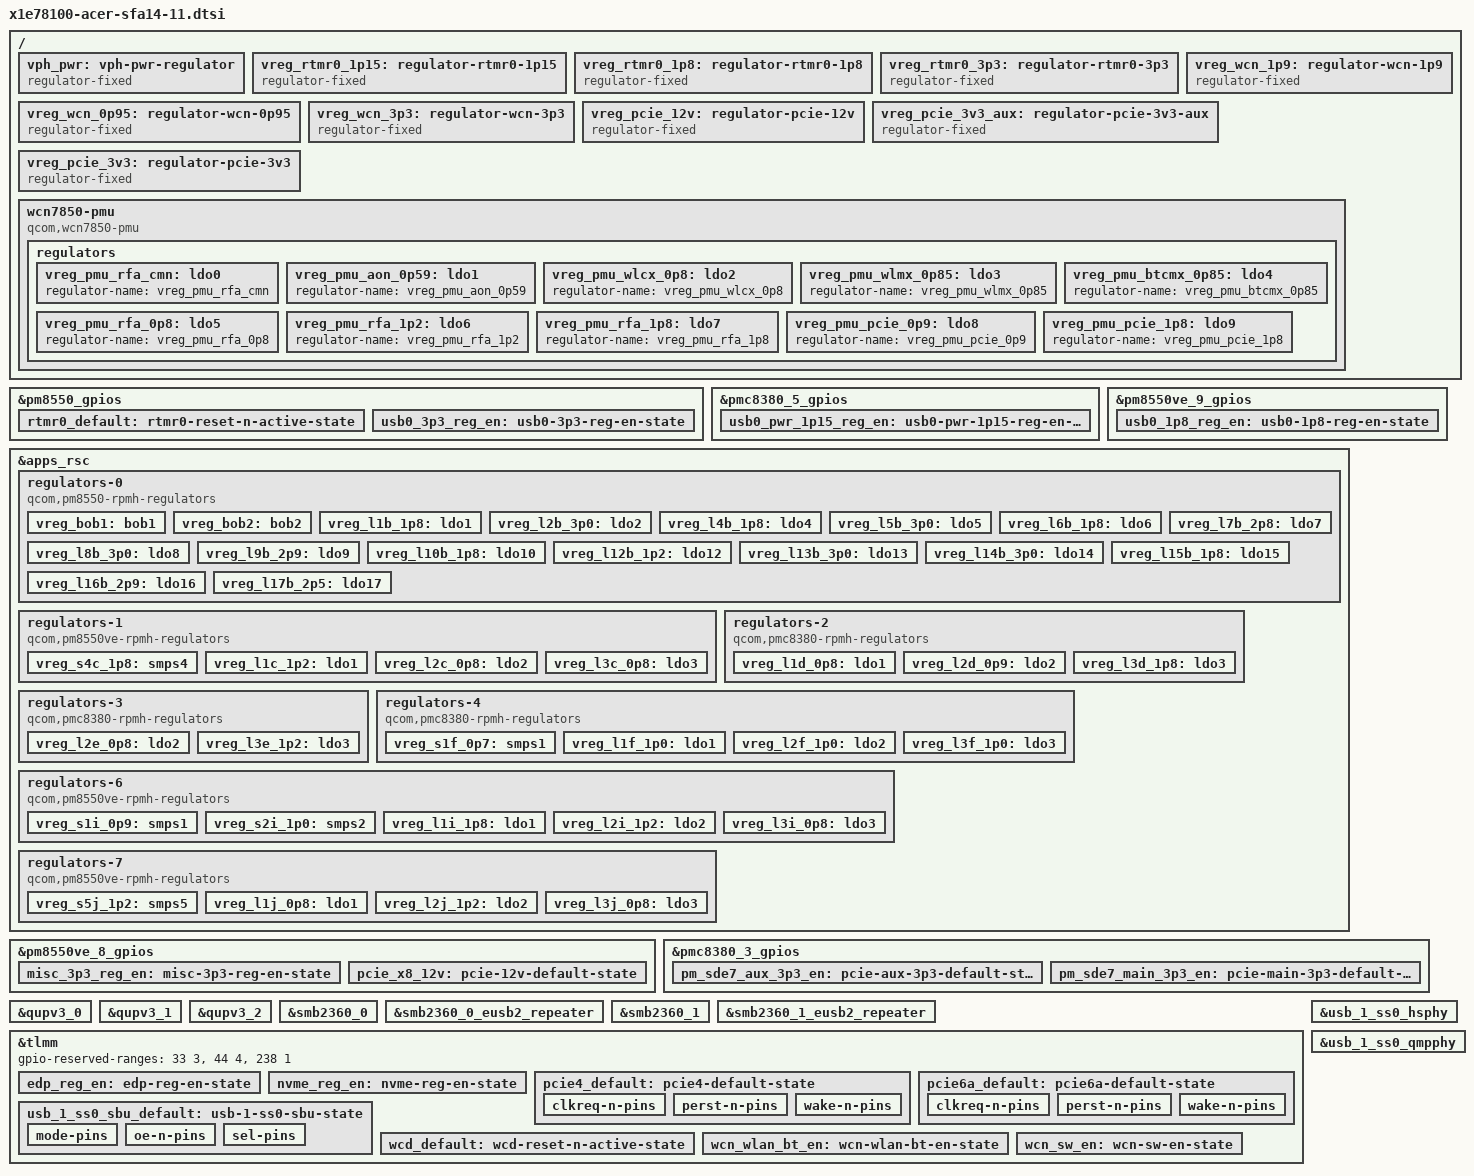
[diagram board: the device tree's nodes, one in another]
// SPDX-License-Identifier: BSD-3-Clause
/*
 * Copyright (c) 2023, Qualcomm Innovation Center, Inc. All rights reserved.
 * Copyright (c) 2025, Linaro Limited
 * Copyright (c) 2025, Zimo Zhang
 */

/dts-v1/;

#include <dt-bindings/gpio/gpio.h>
#include <dt-bindings/pinctrl/qcom,pmic-gpio.h>
#include <dt-bindings/regulator/qcom,rpmh-regulator.h>

#include "hamoa.dtsi"
#include "hamoa-pmics.dtsi"

/ {
	vph_pwr: vph-pwr-regulator {
		compatible = "regulator-fixed";

		regulator-name = "vph_pwr";
		regulator-min-microvolt = <3700000>;
		regulator-max-microvolt = <3700000>;

		regulator-always-on;
		regulator-boot-on;
	};

	vreg_rtmr0_1p15: regulator-rtmr0-1p15 {
		compatible = "regulator-fixed";

		regulator-name = "VREG_RTMR0_1P15";
		regulator-min-microvolt = <1150000>;
		regulator-max-microvolt = <1150000>;

		gpio = <&pmc8380_5_gpios 8 GPIO_ACTIVE_HIGH>;
		enable-active-high;

		pinctrl-0 = <&usb0_pwr_1p15_reg_en>;
		pinctrl-names = "default";

		regulator-boot-on;
	};

	vreg_rtmr0_1p8: regulator-rtmr0-1p8 {
		compatible = "regulator-fixed";

		regulator-name = "VREG_RTMR0_1P8";
		regulator-min-microvolt = <1800000>;
		regulator-max-microvolt = <1800000>;

		gpio = <&pm8550ve_9_gpios 8 GPIO_ACTIVE_HIGH>;
		enable-active-high;

		pinctrl-0 = <&usb0_1p8_reg_en>;
		pinctrl-names = "default";

		regulator-boot-on;
	};

	vreg_rtmr0_3p3: regulator-rtmr0-3p3 {
		compatible = "regulator-fixed";

		regulator-name = "VREG_RTMR0_3P3";
		regulator-min-microvolt = <3300000>;
		regulator-max-microvolt = <3300000>;

		gpio = <&pm8550_gpios 11 GPIO_ACTIVE_HIGH>;
		enable-active-high;

		pinctrl-0 = <&usb0_3p3_reg_en>;
		pinctrl-names = "default";

		regulator-boot-on;
	};

	vreg_wcn_0p95: regulator-wcn-0p95 {
		compatible = "regulator-fixed";

		regulator-name = "VREG_WCN_0P95";
		regulator-min-microvolt = <950000>;
		regulator-max-microvolt = <950000>;

		vin-supply = <&vreg_wcn_3p3>;
	};

	vreg_wcn_1p9: regulator-wcn-1p9 {
		compatible = "regulator-fixed";

		regulator-name = "VREG_WCN_1P9";
		regulator-min-microvolt = <1900000>;
		regulator-max-microvolt = <1900000>;

		vin-supply = <&vreg_wcn_3p3>;
	};

	vreg_wcn_3p3: regulator-wcn-3p3 {
		compatible = "regulator-fixed";

		regulator-name = "VREG_WCN_3P3";
		regulator-min-microvolt = <3300000>;
		regulator-max-microvolt = <3300000>;

		gpio = <&tlmm 214 GPIO_ACTIVE_HIGH>;
		enable-active-high;

		pinctrl-0 = <&wcn_sw_en>;
		pinctrl-names = "default";

		regulator-boot-on;
	};

	vreg_pcie_12v: regulator-pcie-12v {
		compatible = "regulator-fixed";

		regulator-name = "VREG_PCIE_12V";
		regulator-min-microvolt = <12000000>;
		regulator-max-microvolt = <12000000>;

		gpio = <&pm8550ve_8_gpios 8 GPIO_ACTIVE_HIGH>;
		enable-active-high;

		pinctrl-0 = <&pcie_x8_12v>;
		pinctrl-names = "default";
	};

	vreg_pcie_3v3_aux: regulator-pcie-3v3-aux {
		compatible = "regulator-fixed";

		regulator-name = "VREG_PCIE_3P3_AUX";
		regulator-min-microvolt = <3300000>;
		regulator-max-microvolt = <3300000>;

		gpio = <&pmc8380_3_gpios 8 GPIO_ACTIVE_HIGH>;
		enable-active-high;

		pinctrl-0 = <&pm_sde7_aux_3p3_en>;
		pinctrl-names = "default";
	};

	vreg_pcie_3v3: regulator-pcie-3v3 {
		compatible = "regulator-fixed";

		regulator-name = "VREG_PCIE_3P3";
		regulator-min-microvolt = <3300000>;
		regulator-max-microvolt = <3300000>;

		gpio = <&pmc8380_3_gpios 6 GPIO_ACTIVE_HIGH>;
		enable-active-high;

		pinctrl-0 = <&pm_sde7_main_3p3_en>;
		pinctrl-names = "default";
	};

	wcn7850-pmu {
		compatible = "qcom,wcn7850-pmu";

		vdd-supply = <&vreg_wcn_0p95>;
		vddio-supply = <&vreg_l15b_1p8>;
		vddaon-supply = <&vreg_wcn_0p95>;
		vdddig-supply = <&vreg_wcn_0p95>;
		vddrfa1p2-supply = <&vreg_wcn_1p9>;
		vddrfa1p8-supply = <&vreg_wcn_1p9>;

		wlan-enable-gpios = <&tlmm 117 GPIO_ACTIVE_HIGH>;
		bt-enable-gpios = <&tlmm 116 GPIO_ACTIVE_HIGH>;

		pinctrl-0 = <&wcn_wlan_bt_en>;
		pinctrl-names = "default";

		regulators {
			vreg_pmu_rfa_cmn: ldo0 {
				regulator-name = "vreg_pmu_rfa_cmn";
			};

			vreg_pmu_aon_0p59: ldo1 {
				regulator-name = "vreg_pmu_aon_0p59";
			};

			vreg_pmu_wlcx_0p8: ldo2 {
				regulator-name = "vreg_pmu_wlcx_0p8";
			};

			vreg_pmu_wlmx_0p85: ldo3 {
				regulator-name = "vreg_pmu_wlmx_0p85";
			};

			vreg_pmu_btcmx_0p85: ldo4 {
				regulator-name = "vreg_pmu_btcmx_0p85";
			};

			vreg_pmu_rfa_0p8: ldo5 {
				regulator-name = "vreg_pmu_rfa_0p8";
			};

			vreg_pmu_rfa_1p2: ldo6 {
				regulator-name = "vreg_pmu_rfa_1p2";
			};

			vreg_pmu_rfa_1p8: ldo7 {
				regulator-name = "vreg_pmu_rfa_1p8";
			};

			vreg_pmu_pcie_0p9: ldo8 {
				regulator-name = "vreg_pmu_pcie_0p9";
			};

			vreg_pmu_pcie_1p8: ldo9 {
				regulator-name = "vreg_pmu_pcie_1p8";
			};
		};
	};
};

&pm8550_gpios {
	rtmr0_default: rtmr0-reset-n-active-state {
		pins = "gpio10";
		function = "normal";
		power-source = <1>;
		bias-disable;
		input-disable;
		output-enable;
	};

	usb0_3p3_reg_en: usb0-3p3-reg-en-state {
		pins = "gpio11";
		function = "normal";
		power-source = <1>;
		bias-disable;
		input-disable;
		output-enable;
	};
};

&pmc8380_5_gpios {
	usb0_pwr_1p15_reg_en: usb0-pwr-1p15-reg-en-state {
		pins = "gpio8";
		function = "normal";
		power-source = <1>;
		bias-disable;
		input-disable;
		output-enable;
	};
};

&pm8550ve_9_gpios {
	usb0_1p8_reg_en: usb0-1p8-reg-en-state {
		pins = "gpio8";
		function = "normal";
		power-source = <1>;
		bias-disable;
		input-disable;
		output-enable;
	};
};

&apps_rsc {
	regulators-0 {
		compatible = "qcom,pm8550-rpmh-regulators";
		qcom,pmic-id = "b";

		vdd-bob1-supply = <&vph_pwr>;
		vdd-bob2-supply = <&vph_pwr>;
		vdd-l1-l4-l10-supply = <&vreg_s4c_1p8>;
		vdd-l2-l13-l14-supply = <&vreg_bob1>;
		vdd-l5-l16-supply = <&vreg_bob1>;
		vdd-l6-l7-supply = <&vreg_bob2>;
		vdd-l8-l9-supply = <&vreg_bob1>;
		vdd-l12-supply = <&vreg_s5j_1p2>;
		vdd-l15-supply = <&vreg_s4c_1p8>;
		vdd-l17-supply = <&vreg_bob2>;

		vreg_bob1: bob1 {
			regulator-name = "vreg_bob1";
			regulator-min-microvolt = <3008000>;
			regulator-max-microvolt = <3960000>;
			regulator-initial-mode = <RPMH_REGULATOR_MODE_HPM>;
		};

		vreg_bob2: bob2 {
			regulator-name = "vreg_bob2";
			regulator-min-microvolt = <2504000>;
			regulator-max-microvolt = <3008000>;
			regulator-initial-mode = <RPMH_REGULATOR_MODE_HPM>;
		};

		vreg_l1b_1p8: ldo1 {
			regulator-name = "vreg_l1b_1p8";
			regulator-min-microvolt = <1800000>;
			regulator-max-microvolt = <1800000>;
			regulator-initial-mode = <RPMH_REGULATOR_MODE_HPM>;
		};

		vreg_l2b_3p0: ldo2 {
			regulator-name = "vreg_l2b_3p0";
			regulator-min-microvolt = <3072000>;
			regulator-max-microvolt = <3100000>;
			regulator-initial-mode = <RPMH_REGULATOR_MODE_HPM>;
		};

		vreg_l4b_1p8: ldo4 {
			regulator-name = "vreg_l4b_1p8";
			regulator-min-microvolt = <1800000>;
			regulator-max-microvolt = <1800000>;
			regulator-initial-mode = <RPMH_REGULATOR_MODE_HPM>;
		};

		vreg_l5b_3p0: ldo5 {
			regulator-name = "vreg_l5b_3p0";
			regulator-min-microvolt = <3000000>;
			regulator-max-microvolt = <3000000>;
			regulator-initial-mode = <RPMH_REGULATOR_MODE_HPM>;
		};

		vreg_l6b_1p8: ldo6 {
			regulator-name = "vreg_l6b_1p8";
			regulator-min-microvolt = <1800000>;
			regulator-max-microvolt = <2960000>;
			regulator-initial-mode = <RPMH_REGULATOR_MODE_HPM>;
		};

		vreg_l7b_2p8: ldo7 {
			regulator-name = "vreg_l7b_2p8";
			regulator-min-microvolt = <2800000>;
			regulator-max-microvolt = <2800000>;
			regulator-initial-mode = <RPMH_REGULATOR_MODE_HPM>;
		};

		vreg_l8b_3p0: ldo8 {
			regulator-name = "vreg_l8b_3p0";
			regulator-min-microvolt = <3072000>;
			regulator-max-microvolt = <3072000>;
			regulator-initial-mode = <RPMH_REGULATOR_MODE_HPM>;
		};

		vreg_l9b_2p9: ldo9 {
			regulator-name = "vreg_l9b_2p9";
			regulator-min-microvolt = <2960000>;
			regulator-max-microvolt = <2960000>;
			regulator-initial-mode = <RPMH_REGULATOR_MODE_HPM>;
		};

		vreg_l10b_1p8: ldo10 {
			regulator-name = "vreg_l10b_1p8";
			regulator-min-microvolt = <1800000>;
			regulator-max-microvolt = <1800000>;
			regulator-initial-mode = <RPMH_REGULATOR_MODE_HPM>;
		};

		vreg_l12b_1p2: ldo12 {
			regulator-name = "vreg_l12b_1p2";
			regulator-min-microvolt = <1200000>;
			regulator-max-microvolt = <1200000>;
			regulator-initial-mode = <RPMH_REGULATOR_MODE_HPM>;
			regulator-always-on;
		};

		vreg_l13b_3p0: ldo13 {
			regulator-name = "vreg_l13b_3p0";
			regulator-min-microvolt = <3072000>;
			regulator-max-microvolt = <3100000>;
			regulator-initial-mode = <RPMH_REGULATOR_MODE_HPM>;
		};

		vreg_l14b_3p0: ldo14 {
			regulator-name = "vreg_l14b_3p0";
			regulator-min-microvolt = <3072000>;
			regulator-max-microvolt = <3072000>;
			regulator-initial-mode = <RPMH_REGULATOR_MODE_HPM>;
		};

		vreg_l15b_1p8: ldo15 {
			regulator-name = "vreg_l15b_1p8";
			regulator-min-microvolt = <1800000>;
			regulator-max-microvolt = <1800000>;
			regulator-initial-mode = <RPMH_REGULATOR_MODE_HPM>;
			regulator-always-on;
		};

		vreg_l16b_2p9: ldo16 {
			regulator-name = "vreg_l16b_2p9";
			regulator-min-microvolt = <2912000>;
			regulator-max-microvolt = <2912000>;
			regulator-initial-mode = <RPMH_REGULATOR_MODE_HPM>;
		};

		vreg_l17b_2p5: ldo17 {
			regulator-name = "vreg_l17b_2p5";
			regulator-min-microvolt = <2504000>;
			regulator-max-microvolt = <2504000>;
			regulator-initial-mode = <RPMH_REGULATOR_MODE_HPM>;
		};
	};

	regulators-1 {
		compatible = "qcom,pm8550ve-rpmh-regulators";
		qcom,pmic-id = "c";

		vdd-l1-supply = <&vreg_s5j_1p2>;
		vdd-l2-supply = <&vreg_s1f_0p7>;
		vdd-l3-supply = <&vreg_s1f_0p7>;
		vdd-s4-supply = <&vph_pwr>;

		vreg_s4c_1p8: smps4 {
			regulator-name = "vreg_s4c_1p8";
			regulator-min-microvolt = <1856000>;
			regulator-max-microvolt = <2000000>;
			regulator-initial-mode = <RPMH_REGULATOR_MODE_HPM>;
		};

		vreg_l1c_1p2: ldo1 {
			regulator-name = "vreg_l1c_1p2";
			regulator-min-microvolt = <1200000>;
			regulator-max-microvolt = <1200000>;
			regulator-initial-mode = <RPMH_REGULATOR_MODE_HPM>;
		};

		vreg_l2c_0p8: ldo2 {
			regulator-name = "vreg_l2c_0p8";
			regulator-min-microvolt = <880000>;
			regulator-max-microvolt = <920000>;
			regulator-initial-mode = <RPMH_REGULATOR_MODE_HPM>;
		};

		vreg_l3c_0p8: ldo3 {
			regulator-name = "vreg_l3c_0p8";
			regulator-min-microvolt = <880000>;
			regulator-max-microvolt = <920000>;
			regulator-initial-mode = <RPMH_REGULATOR_MODE_HPM>;
		};
	};

	regulators-2 {
		compatible = "qcom,pmc8380-rpmh-regulators";
		qcom,pmic-id = "d";

		vdd-l1-supply = <&vreg_s1f_0p7>;
		vdd-l2-supply = <&vreg_s1f_0p7>;
		vdd-l3-supply = <&vreg_s4c_1p8>;
		vdd-s1-supply = <&vph_pwr>;

		vreg_l1d_0p8: ldo1 {
			regulator-name = "vreg_l1d_0p8";
			regulator-min-microvolt = <880000>;
			regulator-max-microvolt = <920000>;
			regulator-initial-mode = <RPMH_REGULATOR_MODE_HPM>;
		};

		vreg_l2d_0p9: ldo2 {
			regulator-name = "vreg_l2d_0p9";
			regulator-min-microvolt = <912000>;
			regulator-max-microvolt = <920000>;
			regulator-initial-mode = <RPMH_REGULATOR_MODE_HPM>;
		};

		vreg_l3d_1p8: ldo3 {
			regulator-name = "vreg_l3d_1p8";
			regulator-min-microvolt = <1800000>;
			regulator-max-microvolt = <1800000>;
			regulator-initial-mode = <RPMH_REGULATOR_MODE_HPM>;
		};
	};

	regulators-3 {
		compatible = "qcom,pmc8380-rpmh-regulators";
		qcom,pmic-id = "e";

		vdd-l2-supply = <&vreg_s1f_0p7>;
		vdd-l3-supply = <&vreg_s5j_1p2>;

		vreg_l2e_0p8: ldo2 {
			regulator-name = "vreg_l2e_0p8";
			regulator-min-microvolt = <880000>;
			regulator-max-microvolt = <920000>;
			regulator-initial-mode = <RPMH_REGULATOR_MODE_HPM>;
		};

		vreg_l3e_1p2: ldo3 {
			regulator-name = "vreg_l3e_1p2";
			regulator-min-microvolt = <1200000>;
			regulator-max-microvolt = <1200000>;
			regulator-initial-mode = <RPMH_REGULATOR_MODE_HPM>;
		};
	};

	regulators-4 {
		compatible = "qcom,pmc8380-rpmh-regulators";
		qcom,pmic-id = "f";

		vdd-l1-supply = <&vreg_s5j_1p2>;
		vdd-l2-supply = <&vreg_s5j_1p2>;
		vdd-l3-supply = <&vreg_s5j_1p2>;
		vdd-s1-supply = <&vph_pwr>;

		vreg_s1f_0p7: smps1 {
			regulator-name = "vreg_s1f_0p7";
			regulator-min-microvolt = <700000>;
			regulator-max-microvolt = <1100000>;
			regulator-initial-mode = <RPMH_REGULATOR_MODE_HPM>;
		};

		vreg_l1f_1p0: ldo1 {
			regulator-name = "vreg_l1f_1p0";
			regulator-min-microvolt = <1024000>;
			regulator-max-microvolt = <1024000>;
			regulator-initial-mode = <RPMH_REGULATOR_MODE_HPM>;
		};

		vreg_l2f_1p0: ldo2 {
			regulator-name = "vreg_l2f_1p0";
			regulator-min-microvolt = <1024000>;
			regulator-max-microvolt = <1024000>;
			regulator-initial-mode = <RPMH_REGULATOR_MODE_HPM>;
		};

		vreg_l3f_1p0: ldo3 {
			regulator-name = "vreg_l3f_1p0";
			regulator-min-microvolt = <1024000>;
			regulator-max-microvolt = <1024000>;
			regulator-initial-mode = <RPMH_REGULATOR_MODE_HPM>;
		};
	};

	regulators-6 {
		compatible = "qcom,pm8550ve-rpmh-regulators";
		qcom,pmic-id = "i";

		vdd-l1-supply = <&vreg_s4c_1p8>;
		vdd-l2-supply = <&vreg_s5j_1p2>;
		vdd-l3-supply = <&vreg_s1f_0p7>;
		vdd-s1-supply = <&vph_pwr>;
		vdd-s2-supply = <&vph_pwr>;

		vreg_s1i_0p9: smps1 {
			regulator-name = "vreg_s1i_0p9";
			regulator-min-microvolt = <900000>;
			regulator-max-microvolt = <920000>;
			regulator-initial-mode = <RPMH_REGULATOR_MODE_HPM>;
		};

		vreg_s2i_1p0: smps2 {
			regulator-name = "vreg_s2i_1p0";
			regulator-min-microvolt = <1000000>;
			regulator-max-microvolt = <1100000>;
			regulator-initial-mode = <RPMH_REGULATOR_MODE_HPM>;
		};

		vreg_l1i_1p8: ldo1 {
			regulator-name = "vreg_l1i_1p8";
			regulator-min-microvolt = <1800000>;
			regulator-max-microvolt = <1800000>;
			regulator-initial-mode = <RPMH_REGULATOR_MODE_HPM>;
		};

		vreg_l2i_1p2: ldo2 {
			regulator-name = "vreg_l2i_1p2";
			regulator-min-microvolt = <1200000>;
			regulator-max-microvolt = <1200000>;
			regulator-initial-mode = <RPMH_REGULATOR_MODE_HPM>;
		};

		vreg_l3i_0p8: ldo3 {
			regulator-name = "vreg_l3i_0p8";
			regulator-min-microvolt = <880000>;
			regulator-max-microvolt = <920000>;
			regulator-initial-mode = <RPMH_REGULATOR_MODE_HPM>;
		};
	};

	regulators-7 {
		compatible = "qcom,pm8550ve-rpmh-regulators";
		qcom,pmic-id = "j";

		vdd-l1-supply = <&vreg_s1f_0p7>;
		vdd-l2-supply = <&vreg_s5j_1p2>;
		vdd-l3-supply = <&vreg_s1f_0p7>;
		vdd-s5-supply = <&vph_pwr>;

		vreg_s5j_1p2: smps5 {
			regulator-name = "vreg_s5j_1p2";
			regulator-min-microvolt = <1256000>;
			regulator-max-microvolt = <1304000>;
			regulator-initial-mode = <RPMH_REGULATOR_MODE_HPM>;
		};

		vreg_l1j_0p8: ldo1 {
			regulator-name = "vreg_l1j_0p8";
			regulator-min-microvolt = <880000>;
			regulator-max-microvolt = <920000>;
			regulator-initial-mode = <RPMH_REGULATOR_MODE_HPM>;
		};

		vreg_l2j_1p2: ldo2 {
			regulator-name = "vreg_l2j_1p2";
			regulator-min-microvolt = <1256000>;
			regulator-max-microvolt = <1256000>;
			regulator-initial-mode = <RPMH_REGULATOR_MODE_HPM>;
		};

		vreg_l3j_0p8: ldo3 {
			regulator-name = "vreg_l3j_0p8";
			regulator-min-microvolt = <880000>;
			regulator-max-microvolt = <920000>;
			regulator-initial-mode = <RPMH_REGULATOR_MODE_HPM>;
		};
	};
};

&pm8550ve_8_gpios {
	misc_3p3_reg_en: misc-3p3-reg-en-state {
		pins = "gpio6";
		function = "normal";
		bias-disable;
		drive-push-pull;
		input-disable;
		output-enable;
		power-source = <1>; /* 1.8 V */
		qcom,drive-strength = <PMIC_GPIO_STRENGTH_LOW>;
	};

	pcie_x8_12v: pcie-12v-default-state {
		pins = "gpio8";
		function = "normal";
		output-enable;
		output-high;
		bias-pull-down;
		power-source = <0>;
	};
};

&pmc8380_3_gpios {
	pm_sde7_aux_3p3_en: pcie-aux-3p3-default-state {
		pins = "gpio8";
		function = "normal";
		output-enable;
		output-high;
		bias-pull-down;
		power-source = <0>;
	};

	pm_sde7_main_3p3_en: pcie-main-3p3-default-state {
		pins = "gpio6";
		function = "normal";
		output-enable;
		output-high;
		bias-pull-down;
		power-source = <0>;
	};
};

&qupv3_0 {
	status = "okay";
};

&qupv3_1 {
	status = "okay";
};

&qupv3_2 {
	status = "okay";
};

&smb2360_0 {
	status = "okay";
};

&smb2360_0_eusb2_repeater {
	vdd18-supply = <&vreg_l3d_1p8>;
	vdd3-supply = <&vreg_l2b_3p0>;
};

&smb2360_1 {
	status = "okay";
};

&smb2360_1_eusb2_repeater {
	vdd18-supply = <&vreg_l3d_1p8>;
	vdd3-supply = <&vreg_l14b_3p0>;
};

&tlmm {
	gpio-reserved-ranges = <33 3>, /* Unused */
			       <44 4>, /* SPI (TPM) */
			       <238 1>; /* UFS Reset */

	edp_reg_en: edp-reg-en-state {
		pins = "gpio70";
		function = "gpio";
		drive-strength = <16>;
		bias-disable;
	};

	nvme_reg_en: nvme-reg-en-state {
		pins = "gpio18";
		function = "gpio";
		drive-strength = <2>;
		bias-disable;
	};

	pcie4_default: pcie4-default-state {
		clkreq-n-pins {
			pins = "gpio147";
			function = "pcie4_clk";
			drive-strength = <2>;
			bias-pull-up;
		};

		perst-n-pins {
			pins = "gpio146";
			function = "gpio";
			drive-strength = <2>;
			bias-disable;
		};

		wake-n-pins {
			pins = "gpio148";
			function = "gpio";
			drive-strength = <2>;
			bias-pull-up;
		};
	};

	pcie6a_default: pcie6a-default-state {
		clkreq-n-pins {
			pins = "gpio153";
			function = "pcie6a_clk";
			drive-strength = <2>;
			bias-pull-up;
		};

		perst-n-pins {
			pins = "gpio152";
			function = "gpio";
			drive-strength = <2>;
			bias-disable;
		};

		wake-n-pins {
			pins = "gpio154";
			function = "gpio";
			drive-strength = <2>;
			bias-pull-up;
		};
	};

	usb_1_ss0_sbu_default: usb-1-ss0-sbu-state {
		mode-pins {
			pins = "gpio166";
			function = "gpio";
			bias-disable;
			drive-strength = <2>;
			output-high;
		};

		oe-n-pins {
			pins = "gpio168";
			function = "gpio";
			bias-disable;
			drive-strength = <2>;
		};

		sel-pins {
			pins = "gpio167";
			function = "gpio";
			bias-disable;
			drive-strength = <2>;
		};

	};

	wcd_default: wcd-reset-n-active-state {
		pins = "gpio191";
		function = "gpio";
		drive-strength = <16>;
		bias-disable;
		output-low;
	};

	wcn_wlan_bt_en: wcn-wlan-bt-en-state {
		pins = "gpio116", "gpio117";
		function = "gpio";
		drive-strength = <2>;
		bias-disable;
	};

	wcn_sw_en: wcn-sw-en-state {
		pins = "gpio214";
		function = "gpio";
		drive-strength = <2>;
		bias-disable;
	};
};

&usb_1_ss0_hsphy {
	vdd-supply = <&vreg_l3j_0p8>;
	vdda12-supply = <&vreg_l2j_1p2>;

	phys = <&smb2360_0_eusb2_repeater>;

	status = "okay";
};

&usb_1_ss0_qmpphy {
	vdda-phy-supply = <&vreg_l2j_1p2>;
	vdda-pll-supply = <&vreg_l1j_0p8>;

	status = "okay";
};

